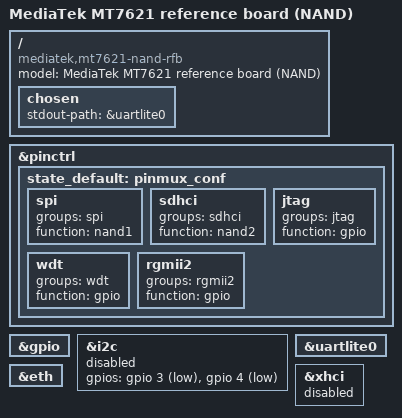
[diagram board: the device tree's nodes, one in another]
// SPDX-License-Identifier: GPL-2.0+
/*
 * Copyright (C) 2018 MediaTek Inc.
 *
 * Author: Weijie Gao <weijie.gao@mediatek.com>
 */

/dts-v1/;
#include "mt7621.dtsi"

/ {
	model = "MediaTek MT7621 reference board (NAND)";
	compatible = "mediatek,mt7621-nand-rfb", "mediatek,mt7621-soc";

	chosen {
		stdout-path = &uartlite0;
	};
};

&pinctrl {
	state_default: pinmux_conf {
		spi {
			groups = "spi";
			function = "nand1";
		};

		sdhci {
			groups = "sdhci";
			function = "nand2";
		};

		jtag {
			groups = "jtag";
			function = "gpio";
		};

		wdt {
			groups = "wdt";
			function = "gpio";
		};

		rgmii2 {
			groups = "rgmii2";
			function = "gpio";
		};
	};
};

&gpio {
	status = "okay";
};

&i2c {
	gpios = <&gpio 3 1>, /* PIN3 as SDA */
		<&gpio 4 1>; /* PIN4 as CLK */
	status = "disabled";
};

&uartlite0 {
	status = "okay";
};

&eth {
	status = "okay";
};

&xhci {
	/* 对齐原厂 U-Boot stage2 内置 DTB（文件偏移 0x04B4B0，total=0xE12）：
	 * 原厂 xhci@1e1c0000 为 status="disabled"，U-Boot 不初始化 USB 控制器，
	 * 把 USB PHY / XHCI 的初始状态完整交给内核（内核用 boot 分区自己的 DTB）。
	 * 本自建 U-Boot 未编入任何 CONFIG_USB_* 驱动（u-boot.map 无 xhci/usb_ 符号），
	 * 这里的 status 只影响 DTB 内容本身，不影响 U-Boot 运行时行为。
	 */
	status = "disabled";
};
